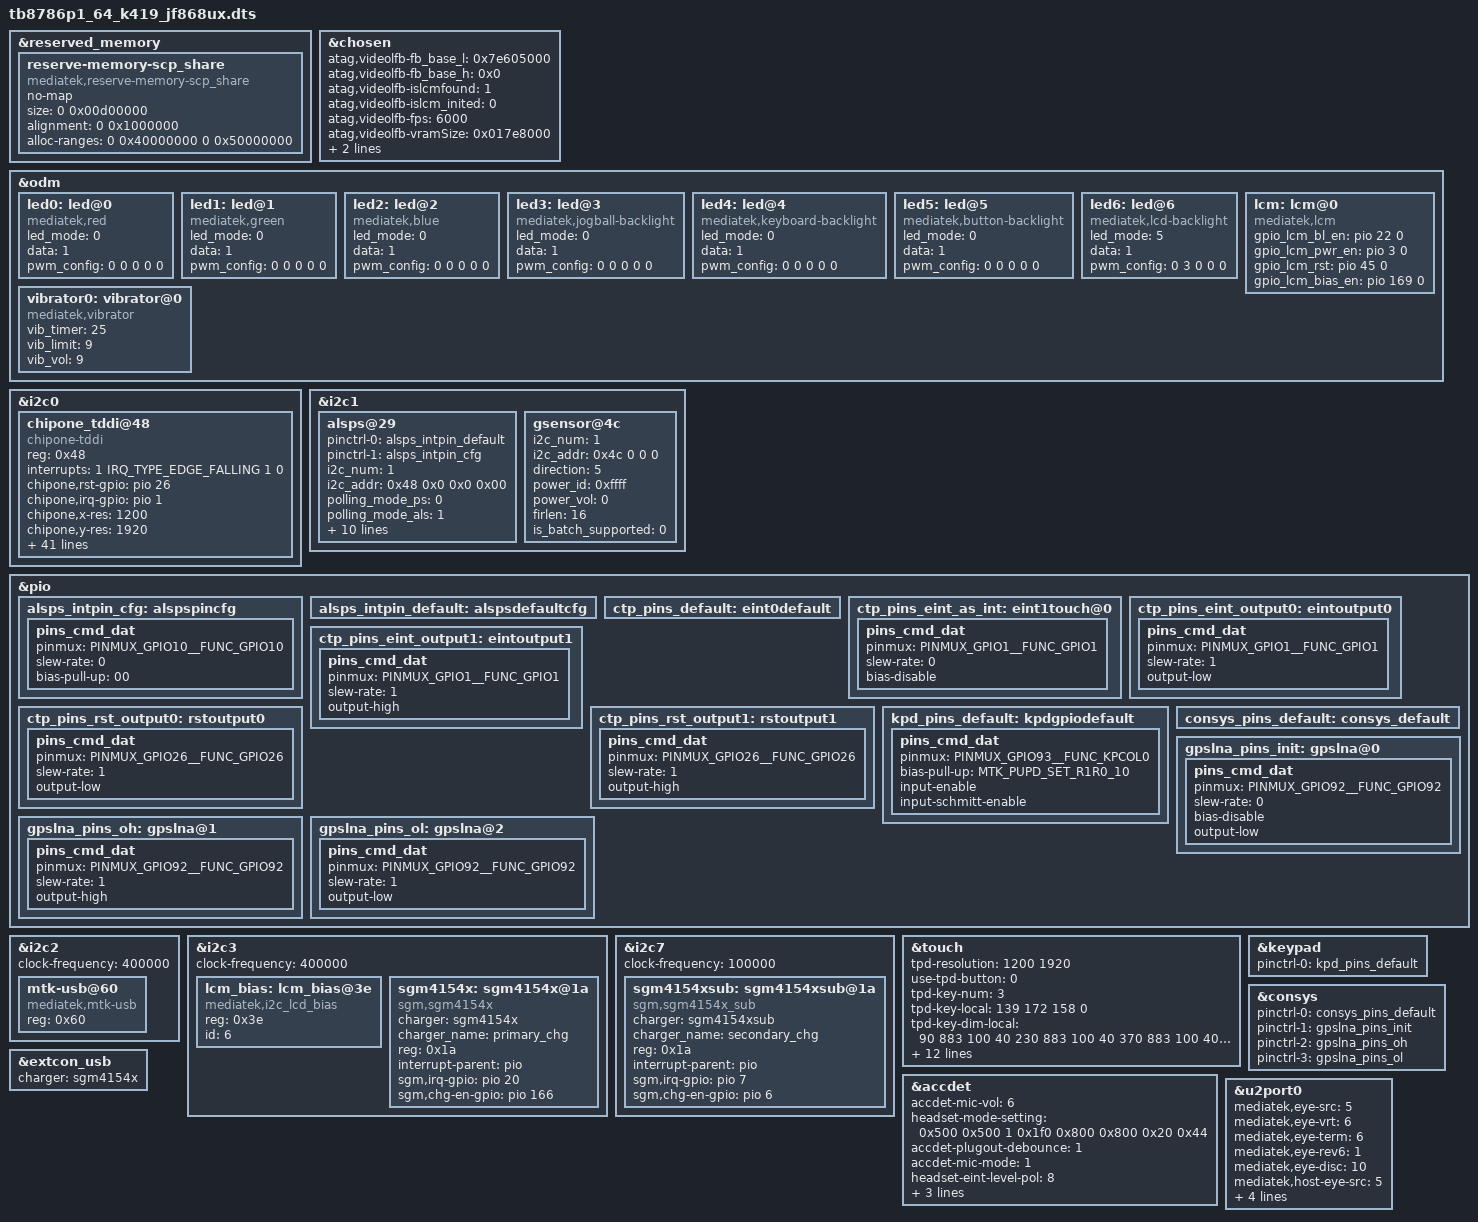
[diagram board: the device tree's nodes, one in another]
// SPDX-License-Identifier: GPL-2.0
/*
 * Copyright (c) 2019 MediaTek Inc.
 */

/dts-v1/;
/plugin/;
#include <dt-bindings/interrupt-controller/irq.h>
#include <dt-bindings/interrupt-controller/arm-gic.h>
#include <dt-bindings/pinctrl/mt6768-pinfunc.h>

&reserved_memory {
    reserve-memory-scp_share {
        compatible = "mediatek,reserve-memory-scp_share";
        no-map;
        size = <0 0x00d00000>;
        alignment = <0 0x1000000>;
        alloc-ranges = <0 0x40000000 0 0x50000000>;
    };
};

/* chosen */
&chosen {

    atag,videolfb-fb_base_l = <0x7e605000>;
    atag,videolfb-fb_base_h = <0x0>;
    atag,videolfb-islcmfound = <1>;
    atag,videolfb-islcm_inited = <0>;
    atag,videolfb-fps= <6000>;
    atag,videolfb-vramSize= <0x017e8000>;
    atag,videolfb-lcmname=
        "hx83112b_fhdp_dsi_cmd_auo_rt5081_drv";
};

&odm {
    led0:led@0 {
        compatible = "mediatek,red";
        led_mode = <0>;
        data = <1>;
        pwm_config = <0 0 0 0 0>;
    };
    led1:led@1 {
        compatible = "mediatek,green";
        led_mode = <0>;
        data = <1>;
        pwm_config = <0 0 0 0 0>;
    };
    led2:led@2 {
        compatible = "mediatek,blue";
        led_mode = <0>;
        data = <1>;
        pwm_config = <0 0 0 0 0>;
    };
    led3:led@3 {
        compatible = "mediatek,jogball-backlight";
        led_mode = <0>;
        data = <1>;
        pwm_config = <0 0 0 0 0>;
    };
    led4:led@4 {
        compatible = "mediatek,keyboard-backlight";
        led_mode = <0>;
        data = <1>;
        pwm_config = <0 0 0 0 0>;
    };
    led5:led@5 {
        compatible = "mediatek,button-backlight";
        led_mode = <0>;
        data = <1>;
        pwm_config = <0 0 0 0 0>;
    };
    led6:led@6 {
        compatible = "mediatek,lcd-backlight";
        led_mode = <5>;
        data = <1>;
        pwm_config = <0 3 0 0 0>;
    };

    lcm: lcm@0{
        compatible = "mediatek,lcm";
        gpio_lcm_bl_en = <&pio 22 0>;              /*bl en*/
        gpio_lcm_pwr_en = <&pio 3 0>;              /*1.8v*/
        gpio_lcm_rst = <&pio 45 0>;                /*reset*/
        gpio_lcm_bias_en = <&pio 169 0>;
        status = "okay";
    };

    vibrator0:vibrator@0 {
        compatible = "mediatek,vibrator";
        vib_timer = <25>;
        vib_limit = <9>;
        vib_vol= <9>;
    };
};

&i2c0 {
    /* cap_touch@40 {
        compatible = "mediatek,cap_touch";
        reg = <0x40>;
        status = "okay";
    }; */

    chipone_tddi@48 {
        compatible = "chipone-tddi";
        reg = <0x48>;
		status = "okay" ;
		interrupts = <1 IRQ_TYPE_EDGE_FALLING 1 0>;
        chipone,rst-gpio = <&pio 26 0x00>;
        chipone,irq-gpio = <&pio 1 0x00>;
        chipone,x-res = <1200>;
        chipone,y-res = <1920>;

        /* Charger detect */
        chipone,touch-charger-detect-enable;
        chipone,touch-charger-detect-type = "notify"; /* notify, poll */
        chipone,touch-charger-detect-psy-name = "charger";
        chipone,touch-charger-detect-psp = "POWER_SUPPLY_PROP_ONLINE";
        chipone,touch-charger-detect-psp-poll-interval = <1000>;

        /* Earjack detect */
        chipone,touch-earjack-detect-enable;
        /* MTK:  /sys/bus/platform/drivers/Accdet_Driver/state,
           Sprd: /sys/kernel/headset/state
           QCOM: None, and disable it */
        chipone,touch-earjack-state-filepath = "/sys/bus/platform/drivers/Accdet_Driver/state";
        chipone,touch-earjack-poll-interval = <1000>;

        /* For tp selftest */
		chipone,test-reset-pin;
		chipone,test-int-pin;
		chipone,test-rawdata;
		chipone,test-rawdata-frames      = <1>;
		chipone,rawdata-min              = <100>;
		chipone,rawdata-max              = <10000>;
		chipone,test-noise;
		chipone,test-noise-frames        = <50>;
		chipone,noise-max                = <1000>;
		chipone,test-open;
		chipone,open-min                 = <200>;
		chipone,test-short;
		chipone,short-min                = <200>;
		chipone,test-compensate-cap;
		chipone,compensate-cap-min       = <1>;
		chipone,compensate-cap-max       = <127>;

		/* gesture data test */
		chipone,test-gesture-rawdata;
		chipone,test-gesture-rawdata-frames = <1>;
		chipone,gesture-rawdata-min = <100>;
		chipone,gesture-rawdata-max = <10000>;

		chipone,test-gesture-lp-rawdata;
		chipone,test-gesture-lp-rawdata-frames = <1>;
		chipone,gesture-lp-rawdata-min = <100>;
		chipone,gesture-lp-rawdata-max = <10000>;

		chipone,test-gesture-noise;
		chipone,test-gesture-noise-frames = <50>;
		chipone,gesture-noise-max = <1000>;

		chipone,test-gesture-lp-noise;
		chipone,test-gesture-lp-noise-frames = <50>;
		chipone,gesture-lp-noise-max = <1000>;
    };
};

&i2c1 {
    alsps@29 {
        pinctrl-names = "pin_default", "pin_cfg";
        pinctrl-0 = <&alsps_intpin_default>;
        pinctrl-1 = <&alsps_intpin_cfg>;
        status = "okay";
        /* customization */
        i2c_num = <1>;
        i2c_addr = <0x48 0x0 0x0 0x00>;
        polling_mode_ps = <0>;
        polling_mode_als = <1>;
        power_id = <0xffff>;
        power_vol = <0>;
        als_level =
            <0 1 1 7 15 15 100 1000 2000 3000
            6000 10000 14000 18000 20000>;
        als_value =
            <40 40 90 90 160 160 225 320 640 1280
            1280 2600 2600 2600 10240 10240>;
        ps_threshold_high = <900>;
        ps_threshold_low = <600>;
        is_batch_supported_ps = <0>;
        is_batch_supported_als = <0>;
    };

    gsensor@4c{
        i2c_num = <1>;
        i2c_addr = <0x4c 0 0 0>;
        direction = <5>;
        power_id = <0xffff>;
        power_vol = <0>;
        firlen = <16>;
        is_batch_supported = <0>;
    };

};

&pio {
    alsps_intpin_cfg: alspspincfg {
        pins_cmd_dat {
            pinmux = <PINMUX_GPIO10__FUNC_GPIO10>;
            slew-rate = <0>;
            bias-pull-up = <00>;
        };
    };

    alsps_intpin_default: alspsdefaultcfg {

    };
};

&i2c2 {
    clock-frequency = <400000>;

    mtk-usb@60 {
        compatible = "mediatek,mtk-usb";
        reg = <0x60>;
        status = "okay";
    };
};

&i2c3 {
    clock-frequency = <400000>;

    lcm_bias: lcm_bias@3e {
        compatible = "mediatek,i2c_lcd_bias";
        reg = <0x3e>;
        id = <6>;
        status = "okay";
    };

    sgm4154x: sgm4154x@1a{
        charger = <&sgm4154x>;
        status = "okay";
        compatible = "sgm,sgm4154x";
        charger_name = "primary_chg";
        reg = <0x1a>;
        interrupt-parent = <&pio>;
        /*interrupts = <0 0>;*/                                               /*irq num base on hardware design*/
        sgm,irq-gpio = <&pio 20 0>;                    /*irq num base on hardware design*/
        sgm,chg-en-gpio = <&pio 166 0>;                /*gpio num base on hardware design*/
    };
};

&i2c7 {
    clock-frequency = <100000>;

    sgm4154xsub: sgm4154xsub@1a{
        charger = <&sgm4154xsub>;
        status = "okay";
        compatible = "sgm,sgm4154x_sub";
        charger_name = "secondary_chg";
        reg = <0x1a>;
        interrupt-parent = <&pio>;
        /*interrupts = <0 0>;*/                                               /*irq num base on hardware design*/
        sgm,irq-gpio = <&pio 7 0>;                     /*irq num base on hardware design*/
        sgm,chg-en-gpio = <&pio 6 0>;                  /*gpio num base on hardware design*/
    };
};
    
/* TOUCH start */
&touch {
    tpd-resolution = <1200 1920>;
    use-tpd-button = <0>;
    tpd-key-num = <3>;
    tpd-key-local= <139 172 158 0>;
    tpd-key-dim-local = <90 883 100 40 230
                 883 100 40 370 883 100 40 0 0 0 0>;
    tpd-max-touch-num = <10>;
    tpd-filter-enable = <0>;
    tpd-filter-pixel-density = <106>;
    tpd-filter-custom-prameters = <0 0 0 0 0 0 0 0 0 0 0 0>;
    tpd-filter-custom-speed = <0 0 0>;
    pinctrl-names = "default", "state_eint_as_int", "state_eint_output0",
        "state_eint_output1", "state_rst_output0", "state_rst_output1";
    pinctrl-0 = <&ctp_pins_default>;
    pinctrl-1 = <&ctp_pins_eint_as_int>;
    pinctrl-2 = <&ctp_pins_eint_output0>;
    pinctrl-3 = <&ctp_pins_eint_output1>;
    pinctrl-4 = <&ctp_pins_rst_output0>;
    pinctrl-5 = <&ctp_pins_rst_output1>;
    status = "okay";
};
&pio {

    ctp_pins_default: eint0default {
    };
    ctp_pins_eint_as_int: eint1touch@0 {
        pins_cmd_dat {
            pinmux = <PINMUX_GPIO1__FUNC_GPIO1>;
            slew-rate = <0>;
            bias-disable;
        };
    };
    ctp_pins_eint_output0: eintoutput0 {
        pins_cmd_dat {
            pinmux = <PINMUX_GPIO1__FUNC_GPIO1>;
            slew-rate = <1>;
            output-low;
        };
    };
    ctp_pins_eint_output1: eintoutput1 {
        pins_cmd_dat {
            pinmux = <PINMUX_GPIO1__FUNC_GPIO1>;
            slew-rate = <1>;
            output-high;
        };
    };
    ctp_pins_rst_output0: rstoutput0 {
        pins_cmd_dat {
            pinmux = <PINMUX_GPIO26__FUNC_GPIO26>;
            slew-rate = <1>;
            output-low;
        };
    };
    ctp_pins_rst_output1: rstoutput1 {
        pins_cmd_dat {
            pinmux = <PINMUX_GPIO26__FUNC_GPIO26>;
            slew-rate = <1>;
            output-high;
        };
    };
};
/* TOUCH end */

/* accdet start */
&accdet {
    /* accdet micbias voltage: 0x07,2.7v;0x05,2.5v;0x02,1.9v */
    accdet-mic-vol = <6>;
    headset-mode-setting = <0x500 0x500 1 0x1f0 0x800 0x800 0x20 0x44>;
    accdet-plugout-debounce = <1>;
    /*1:ACC mode, 2:low cost without in bias, 6:low cost with in bias*/
    accdet-mic-mode = <1>;
    /* eint_level_trigger: 8,LEVEL_LOW(DEF) ;4,LV_HIGH;others,LV_LOW */
    headset-eint-level-pol = <8>;
    /*0--MD_MAX--UP_MAX--DW_MAX*/
    headset-three-key-threshold = <0 80 220 400>;
    headset-three-key-threshold-CDD = <0 121 192 600>;
    /*0--MD_MAX--VOICE_MAX--UP_MAX--DW_MAX*/
    headset-four-key-threshold = <0 58 121 192 400>;
    status = "okay";
};
/* accdet end */

/* keypad start */
&keypad {
    pinctrl-names = "default";
    pinctrl-0 = <&kpd_pins_default>;
};

&pio {
    kpd_pins_default: kpdgpiodefault {
        pins_cmd_dat {
            pinmux = <PINMUX_GPIO93__FUNC_KPCOL0>;
            bias-pull-up = <MTK_PUPD_SET_R1R0_10>;
            input-enable;
            input-schmitt-enable;
        };
    };
};
/* keypad end */


/* CONSYS GPIO standardization */
&pio {
    consys_pins_default: consys_default {
    };
    gpslna_pins_init: gpslna@0 {
        pins_cmd_dat {
            pinmux = <PINMUX_GPIO92__FUNC_GPIO92>;
            slew-rate = <0>;
            bias-disable;
            output-low;
        };
    };
    gpslna_pins_oh: gpslna@1 {
        pins_cmd_dat {
            pinmux = <PINMUX_GPIO92__FUNC_GPIO92>;
            slew-rate = <1>;
            output-high;
        };
    };
    gpslna_pins_ol: gpslna@2 {
        pins_cmd_dat {
            pinmux = <PINMUX_GPIO92__FUNC_GPIO92>;
            slew-rate = <1>;
            output-low;
        };
    };
};
&consys {
    pinctrl-names = "default", "gps_lna_state_init",
        "gps_lna_state_oh", "gps_lna_state_ol";
    pinctrl-0 = <&consys_pins_default>;
    pinctrl-1 = <&gpslna_pins_init>;
    pinctrl-2 = <&gpslna_pins_oh>;
    pinctrl-3 = <&gpslna_pins_ol>;
    status = "okay";
};
/* CONSYS end */


/* DISPSYS GPIO standardization end*/

&extcon_usb {
    charger = <&sgm4154x>;
    /* id-gpios = <&pio 9 0x0>; */
};

&u2port0 {
    mediatek,eye-src = <5>;
    mediatek,eye-vrt = <6>;
    mediatek,eye-term = <6>;
    mediatek,eye-rev6 = <1>;
    mediatek,eye-disc = <10>;
    mediatek,host-eye-src = <5>;
    mediatek,host-eye-vrt = <6>;
    mediatek,host-eye-term = <6>;
    mediatek,host-eye-rev6 = <1>;
    mediatek,host-eye-disc = <10>;
};
            
#include <tb8786p1_64_k419/cust.dtsi>
#include "mediatek/tcpc_config-husb311.dtsi"
#include "mediatek/cust_mt6768_camera_jf868.dtsi"
/*End of this file, DO NOT ADD ANYTHING HERE*/
